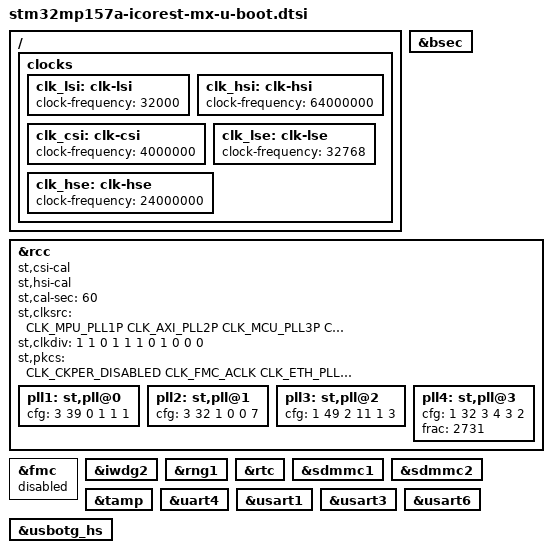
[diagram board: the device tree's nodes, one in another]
/* SPDX-License-Identifier: GPL-2.0+ OR BSD-3-Clause*/
/*
 * Copyright (C) 2020, STMicroelectronics - All Rights Reserved
 * Author: STM32CubeMX code generation for STMicroelectronics.
 */

/* For more information on Device Tree configuration, please refer to
 * https://wiki.st.com/stm32mpu/wiki/Category:Device_tree_configuration
 */

#include <dt-bindings/clock/stm32mp1-clksrc.h>
#include "stm32mp15-icore-mx.dtsi"

#include "stm32mp15-u-boot.dtsi"
#include "stm32mp15-ddr.dtsi"

/ {
	/* FROM KERNEL DTS*/
	clocks {
		#ifndef CONFIG_STM32MP1_TRUSTED
		clk_lsi: clk-lsi {
			clock-frequency = <32000>;
		};
		clk_hsi: clk-hsi {
			clock-frequency = <64000000>;
		};
		clk_csi: clk-csi {
			clock-frequency = <4000000>;
		};
		clk_lse: clk-lse {
			clock-frequency = <32768>;
		};
		clk_hse: clk-hse {
			clock-frequency = <24000000>;
		};
		#endif	/*CONFIG_STM32MP1_TRUSTED*/
		};


};

/* FROM TFA (NOT THE SAME) */
&bsec{
	status = "okay";
};


&rcc {
	st,csi-cal;
	st,hsi-cal;
	st,cal-sec = <60>;
	st,clksrc = <
		CLK_MPU_PLL1P
		CLK_AXI_PLL2P
		CLK_MCU_PLL3P
		CLK_PLL12_HSI
		CLK_PLL3_HSE
		CLK_PLL4_HSE
		CLK_RTC_LSE
		CLK_MCO1_DISABLED
		CLK_MCO2_DISABLED
	>;
	st,clkdiv = <
		1 		/*MPU*/
		1 		/*AXI*/
		0 		/*MCU*/
		1 		/*APB1*/
		1 		/*APB2*/
		1 		/*APB3*/
		0 		/*APB4*/
		1 		/*APB5*/
		0 		/*RTC*/
		0 		/*MCO1*/
		0 		/*MCO2*/
	>;
	st,pkcs = <
		CLK_CKPER_DISABLED
		CLK_FMC_ACLK
		CLK_ETH_PLL3Q
		CLK_SDMMC12_HSI
		CLK_DSI_DSIPLL
		CLK_STGEN_HSI
		CLK_USBPHY_HSE
		CLK_SPI2S1_DISABLED
		CLK_SPI2S23_DISABLED
		CLK_SPI45_DISABLED
		CLK_SPI6_DISABLED
		CLK_I2C46_PCLK5
		CLK_SDMMC3_DISABLED
		CLK_USBO_USBPHY
		CLK_ADC_PLL4R
		CLK_CEC_DISABLED
		CLK_I2C12_PCLK1
		CLK_I2C35_DISABLED
		CLK_UART1_HSI
		CLK_UART24_HSE
		CLK_UART35_PCLK1
		CLK_UART6_DISABLED
		CLK_UART78_DISABLED
		CLK_SPDIF_DISABLED
		CLK_FDCAN_HSE
    CLK_SAI1_PLL4Q
    CLK_SAI2_PLL3Q
		CLK_SAI3_DISABLED
		CLK_SAI4_DISABLED
		CLK_LPTIM1_DISABLED
		CLK_LPTIM23_DISABLED
		CLK_LPTIM45_DISABLED
	>;
    pll1:st,pll@0 {
        cfg = < 3 39 0 1 1 1>;
    };
    pll2:st,pll@1 {
        cfg = < 3 32 1 0 0 7>;
    };
    pll3:st,pll@2 {
        cfg = < 1 49 2 11 1 3>;
    };
    pll4:st,pll@3 {
        cfg = < 1 32 3 4 3 2>;
        frac = < 2731 >;
    };
};

&fmc{
	status = "disabled";
};

&iwdg2{
	status = "okay";
};

&rcc{
	status = "okay";
};

&rng1{
	status = "okay";
};

&rtc{
	status = "okay";
};

&sdmmc1 {
	status = "okay";
};

&sdmmc2{
	status = "okay";
};

&tamp{
	status = "okay";
};

&uart4{
	status = "okay";
};

&usart1{
	status = "okay";
};

&usart3{
	status = "okay";
};

&usart6{
	status = "okay";
};

&usbotg_hs{
	status = "okay";
};


/* USER CODE BEGIN addons */
/* USER CODE END addons */
